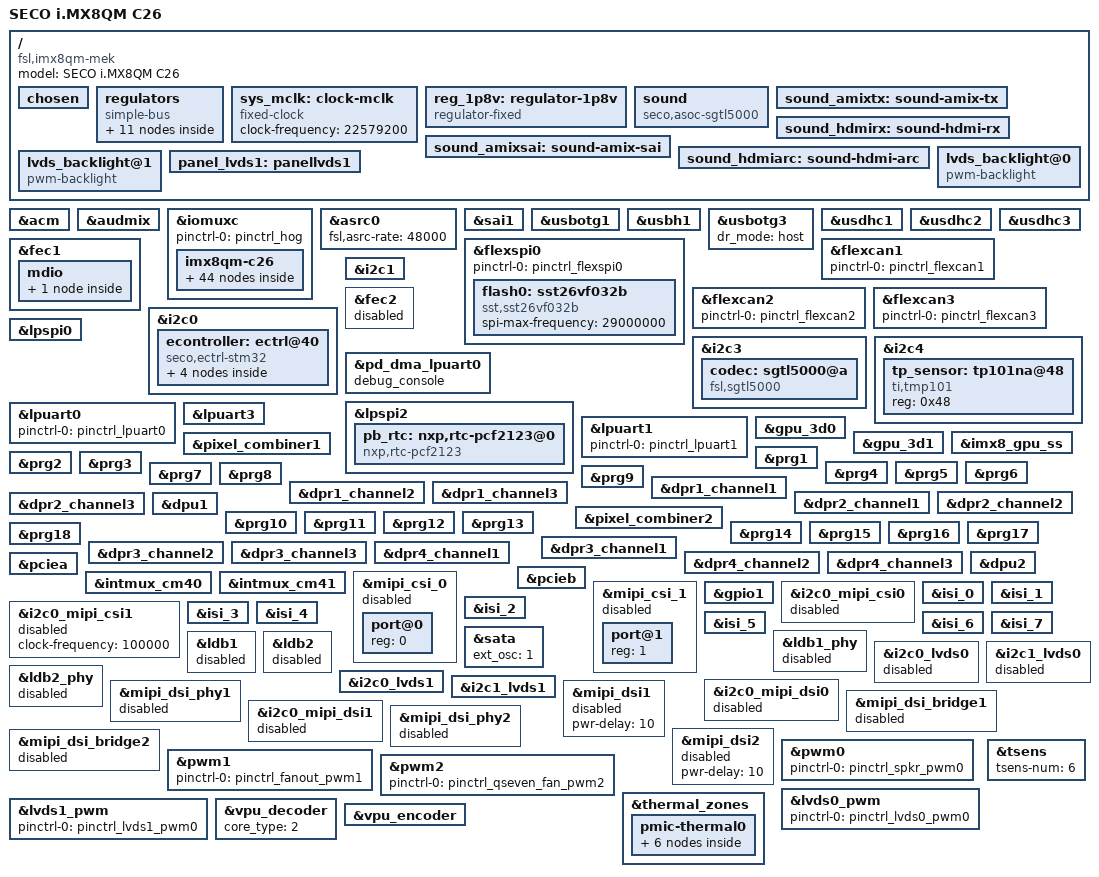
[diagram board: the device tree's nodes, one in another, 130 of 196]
/*
 * Copyright 2017-2018 NXP
 *
 * This program is free software; you can redistribute it and/or
 * modify it under the terms of the GNU General Public License
 * as published by the Free Software Foundation; either version 2
 * of the License, or (at your option) any later version.
 *
 * This program is distributed in the hope that it will be useful,
 * but WITHOUT ANY WARRANTY; without even the implied warranty of
 * MERCHANTABILITY or FITNESS FOR A PARTICULAR PURPOSE.  See the
 * GNU General Public License for more details.
 */

/dts-v1/;

#include <dt-bindings/usb/pd.h>
#include "seco-imx8qm.dtsi"
#include "dt-bindings/net/ti-dp83867.h"
#include "dt-bindings/seco/ectrl_stm32.h"

/ {
	model = "SECO i.MX8QM C26";
	compatible = "fsl,imx8qm-mek","seco,imx8qm-c26","fsl,imx8qm";

	chosen {
		bootargs = "console=ttyLP0,115200 earlycon=lpuart32,0x5a060000,115200";
		stdout-path = &lpuart0;
	};

	regulators {
		compatible = "simple-bus";
		#address-cells = <1>;
		#size-cells = <0>;

		reg_usdhc2_vmmc: usdhc2_vmmc {
			compatible = "regulator-fixed";
			regulator-name = "sw-3p3-sd1";
			regulator-min-microvolt = <3300000>;
			regulator-max-microvolt = <3300000>;
			gpio = <&gpio4 7 GPIO_ACTIVE_HIGH>;
			off-on-delay = <4800>;
			enable-active-high;
		};

		reg_usdhc3_vmmc: usdhc3_vmmc {
			compatible = "regulator-fixed";
			regulator-name = "sw-3p3-sd2";
			regulator-min-microvolt = <3300000>;
			regulator-max-microvolt = <3300000>;
			gpio = <&gpio4 9 GPIO_ACTIVE_HIGH>;
			off-on-delay = <4800>;
			enable-active-high;
		};

		reg_usdhc3_sdiopwr: usdhc3_sdiopwr {
			compatible = "regulator-fixed";
			regulator-name = "sw-3p3-sd2-sdiopwr";
			regulator-min-microvolt = <3300000>;
			regulator-max-microvolt = <3300000>;
			gpio = <&gpio2 4 GPIO_ACTIVE_LOW>;
			regulator-always-on;
			enable-active-low;
			regulator-boot-on;
		};

		reg_vref_1v8: adc_vref_1v8 {
			compatible = "regulator-fixed";
			regulator-name = "vref_1v8";
			regulator-min-microvolt = <1800000>;
			regulator-max-microvolt = <1800000>;
		};

		reg_usb_hsic_rst: usb_hsicrst {
			compatible = "regulator-fixed";
			regulator-name = "HSIC RST";
			regulator-min-microvolt = <3300000>;
			regulator-max-microvolt = <3300000>;
			gpio = <&gpio4 6 GPIO_ACTIVE_HIGH>;
			enable-active-high;
			regulator-always-on;
		};

                pcie_clk_oe_1: pcie_clk_oe1 {
                        compatible = "regulator-fixed";
                        regulator-name = "PCIE_CLK_OE_1";
                        regulator-min-microvolt = <3300000>;
                        regulator-max-microvolt = <3300000>;
                        gpio = <&gpio6 12 GPIO_ACTIVE_HIGH>;
                        enable-active-high;
                        regulator-always-on;
                };

                pcie_clk_oe_2: pcie_clk_oe2 {
                        compatible = "regulator-fixed";
                        regulator-name = "PCIE_CLK_OE_2";
                        regulator-min-microvolt = <3300000>;
                        regulator-max-microvolt = <3300000>;
                        gpio = <&gpio6 13 GPIO_ACTIVE_HIGH>;
                        enable-active-high;
                        regulator-always-on;
                };

                usb_hub_reset: usb_hubrst {
                        compatible = "regulator-fixed";
                        regulator-name = "USB_RST";
                        regulator-min-microvolt = <3300000>;
                        regulator-max-microvolt = <3300000>;
                        gpio = <&gpio4 3 GPIO_ACTIVE_HIGH>;
                        enable-active-high;
                        regulator-always-on;
                };

                lvds_ppen: lvdsppen {
                        compatible = "regulator-fixed";
                        regulator-name = "LVDS_PPEN";
                        regulator-min-microvolt = <3300000>;
                        regulator-max-microvolt = <3300000>;
                        gpio = <&gpio1 5 GPIO_ACTIVE_HIGH>;
                        enable-active-high;
                        regulator-always-on;
			regulator-boot-on;
                };

                lvds_blken: lvdsblken {
                        compatible = "regulator-fixed";
                        regulator-name = "LVDS_BLEN";
                        regulator-min-microvolt = <3300000>;
                        regulator-max-microvolt = <3300000>;
                        gpio = <&gpio2 7 GPIO_ACTIVE_HIGH>;
                        enable-active-high;
                        regulator-always-on;
			regulator-boot-on;
                };

                otg1_pwr_en: otg1_pwren {
                        compatible = "regulator-fixed";
                        regulator-name = "OTG1 PWR EN";
                        regulator-min-microvolt = <3300000>;
                        regulator-max-microvolt = <3300000>;
                        gpio = <&gpio2 19 GPIO_ACTIVE_HIGH>;
                        enable-active-high;
                };
	};

        sys_mclk: clock-mclk {
                compatible = "fixed-clock";
                #clock-cells = <0>;
                clock-frequency = <22579200>;
        };

        reg_1p8v: regulator-1p8v {
                compatible = "regulator-fixed";
                regulator-name = "1P8V";
                regulator-min-microvolt = <1800000>;
                regulator-max-microvolt = <1800000>;
                regulator-always-on;
        };

	sound {
		 compatible = "seco,asoc-sgtl5000";
                model = "seco_sgtl5000";
                cpu-dai = <&sai1>;
                audio-codec = <&codec>;
                /*asrc-controller = <&asrc0>;*/
                status = "okay";

	};

	sound_amixtx: sound-amix-tx {

        };

	sound_hdmirx: sound-hdmi-rx {

	};
	
	sound_amixsai: sound-amix-sai {
	};

	sound_hdmiarc: sound-hdmi-arc {

	};

	lvds_backlight@0 {
		compatible = "pwm-backlight";
		pwms = <&lvds0_pwm 0 100000 0>;

		brightness-levels = < 0  1  2  3  4  5  6  7  8  9
				     10 11 12 13 14 15 16 17 18 19
				     20 21 22 23 24 25 26 27 28 29
				     30 31 32 33 34 35 36 37 38 39
				     40 41 42 43 44 45 46 47 48 49
				     50 51 52 53 54 55 56 57 58 59
				     60 61 62 63 64 65 66 67 68 69
				     70 71 72 73 74 75 76 77 78 79
				     80 81 82 83 84 85 86 87 88 89
				     90 91 92 93 94 95 96 97 98 99
				    100>;
		default-brightness-level = <80>;
	};

	lvds_backlight@1 {
		compatible = "pwm-backlight";
		pwms = <&lvds1_pwm 0 100000 0>;

		brightness-levels = < 0  1  2  3  4  5  6  7  8  9
				     10 11 12 13 14 15 16 17 18 19
				     20 21 22 23 24 25 26 27 28 29
				     30 31 32 33 34 35 36 37 38 39
				     40 41 42 43 44 45 46 47 48 49
				     50 51 52 53 54 55 56 57 58 59
				     60 61 62 63 64 65 66 67 68 69
				     70 71 72 73 74 75 76 77 78 79
				     80 81 82 83 84 85 86 87 88 89
				     90 91 92 93 94 95 96 97 98 99
				    100>;
		default-brightness-level = <80>;
	};
};

&acm {
	status = "okay";
};

&audmix {
	status = "okay";
};

&iomuxc {
	pinctrl-names = "default";
	pinctrl-0 = <&pinctrl_hog>;

	imx8qm-c26 {
		pinctrl_hog: hoggrp {
			fsl,pins = <
				SC_P_MCLK_OUT0_AUD_ACM_MCLK_OUT0	0x0600004c
				SC_P_QSPI1A_DATA1_LSIO_GPIO4_IO25	0x0600004c
				SC_P_SCU_GPIO0_03_LSIO_GPIO0_IO31	0x0600004c
				SC_P_USB_SS3_TC3_LSIO_GPIO4_IO06	0x00000021
				/* SDIO_PWR */
				SC_P_ESAI1_FSR_LSIO_GPIO2_IO04		0x00000021
				/* PCIE CLK OE 1 */
				SC_P_ENET1_RGMII_TXD0_LSIO_GPIO6_IO12	0x00000021
				/* PCIE CLK OE 0 */
				SC_P_ENET1_RGMII_TXD1_LSIO_GPIO6_IO13	0x00000021
				/* USB HUB RESET */
				SC_P_USB_SS3_TC0_LSIO_GPIO4_IO03	0x00000021	
				/* LVDS0 */
				SC_P_LVDS0_GPIO01_LSIO_GPIO1_IO05	0x00000021 /* LVDS_PPEN */	
				SC_P_ESAI1_SCKT_LSIO_GPIO2_IO07		0x00000021 /* LVDS_BLEN */
				/* OTG1 PWR EN */
				SC_P_SPI3_SDI_LSIO_GPIO2_IO19		0x00000021
				/* Generic Gpios */
				SC_P_QSPI1A_SCLK_LSIO_GPIO4_IO21	0x00000021 /* Q7_GPIO0 */
				SC_P_QSPI1A_SS0_B_LSIO_GPIO4_IO19	0x00000021 /* Q7_GPIO1 */	
				SC_P_QSPI1A_SS1_B_LSIO_GPIO4_IO20	0x00000021 /* Q7_GPIO2 */
				SC_P_QSPI1A_DQS_LSIO_GPIO4_IO22		0x00000021 /* Q7_GPIO3 */
				SC_P_QSPI1A_DATA0_LSIO_GPIO4_IO26	0x00000021 /* Q7_GPIO4 */	
				SC_P_QSPI1A_DATA1_LSIO_GPIO4_IO25	0x00000021 /* Q7_GPIO5 */	
				SC_P_QSPI1A_DATA2_LSIO_GPIO4_IO24	0x00000021 /* Q7_GPIO6 */	
				SC_P_QSPI1A_DATA3_LSIO_GPIO4_IO23	0x00000021 /* Q7_GPIO7 */	
				SC_P_SPI3_SCK_LSIO_GPIO2_IO17		0x00000021 /* Q7_GPIO_OUT0 */ 
				/* Gpio switches */
				SC_P_SCU_GPIO0_05_LSIO_GPIO1_IO01	0x00000021 /* BOARD_HOT */
				SC_P_ESAI0_SCKT_LSIO_GPIO2_IO25		0x00000021 /* HDMI_IN_MUX_SEL1 */
				SC_P_ESAI0_TX0_LSIO_GPIO2_IO26		0x00000021 /* HDMI_IN_MUX_SEL2 */
				SC_P_ESAI0_TX1_LSIO_GPIO2_IO27		0x00000021 /* HDMI_IN_MUX_EN */
				SC_P_ESAI0_TX2_RX3_LSIO_GPIO2_IO28	0x00000021 /* USDHC1_VCC_EN */
				SC_P_ESAI0_TX3_RX2_LSIO_GPIO2_IO29	0x00000021 /* USDHC2_VCC_EN */
				/* SECO_CODE */
				SC_P_SIM0_CLK_LSIO_GPIO0_IO00		0x00000021 /* SECO_CODE_0 */	
				SC_P_SIM0_IO_LSIO_GPIO0_IO02		0x00000021 /* SECO_CODE_1 */ 	
				SC_P_SIM0_RST_LSIO_GPIO0_IO01		0x00000021 /* SECO_CODE_2 */	
				SC_P_SIM0_GPIO0_00_LSIO_GPIO0_IO05	0x00000021 /* SECO_CODE_3 */	
				
				SC_P_ESAI0_SCKT_LSIO_GPIO2_IO25		0x00000021 /* HDMI_IN_MUX_SEL1 */
				SC_P_ESAI0_TX0_LSIO_GPIO2_IO26		0x00000021 /* HDMI_IN_MUX_SEL2 */	
				SC_P_ESAI0_TX1_LSIO_GPIO2_IO27		0x00000021 /* HDMI_IN_MUX_EN */	
				/* STM32 Pins */
				SC_P_ESAI0_TX4_RX1_LSIO_GPIO2_IO30	0x00000021 /* From ectrl to SoC */
				SC_P_ESAI0_TX5_RX0_LSIO_GPIO2_IO31	0x00000021 /* From SoC to ectrl */
				SC_P_GPT1_CLK_LSIO_GPIO0_IO17		0x00000021 /* SMB_ALERT# */	
				/* USB Over Current signals */
				SC_P_ESAI1_TX5_RX0_LSIO_GPIO2_IO13	0x00000021 /* USB_01_OC# - GPIO 45 */
				SC_P_ESAI1_TX4_RX1_LSIO_GPIO2_IO12	0x00000021 /* USB_23_OC# - GPIO 44 */
				SC_P_ESAI1_TX3_RX2_LSIO_GPIO2_IO11	0x00000021 /* USB_45_OC# - GPIO 43 */	
				SC_P_ESAI1_TX2_RX3_LSIO_GPIO2_IO10	0x00000021 /* USB_67_OC# - GPIO 42 */	
				/* Audio */
				SC_P_SPDIF0_TX_LSIO_GPIO2_IO15		0x00000021 /* AUD_RST# */	
				/* HDMI IN - Mux Sel */
				SC_P_ESAI0_SCKT_LSIO_GPIO2_IO25		0x00000021 /* HDMI IN - HDMI_IN_MUX_SEL1 */
				SC_P_ESAI0_TX0_LSIO_GPIO2_IO26		0x00000021 /* HDMI IN - HDMI_IN_MUX_SEL2 */
				SC_P_ESAI0_TX1_LSIO_GPIO2_IO27		0x00000021 /* HDMI IN - HDMI_IN_MUX_EN */	
				SC_P_ENET1_RGMII_RXD0_LSIO_GPIO6_IO18	0x00000021 /* HDMI IN - HDMI_RX_EN */
				/* Input Signals */
				SC_P_ESAI0_FSR_LSIO_GPIO2_IO22		0x00000021 /* otg - USB_VBUS_3V3 */	
				SC_P_ESAI1_FST_LSIO_GPIO2_IO05		0x00000021 /* THRMTRIP# */
				SC_P_ESAI1_SCKR_LSIO_GPIO2_IO06		0x00000021 /* THRM# */	
				SC_P_SPI3_SCK_LSIO_GPIO2_IO17		0x00000021 /* QSEVEN_GPIO_OUT0 */
				SC_P_SPI3_SDO_LSIO_GPIO2_IO18		0x00000021 /* SATA_LED */	
				SC_P_SPDIF0_RX_LSIO_GPIO2_IO14		0x00000021 /* RTC_INT */	
				SC_P_SPI3_CS0_LSIO_GPIO2_IO20		0x00000021 /* PMIC1_FSOB */
				SC_P_SPI3_CS1_LSIO_GPIO2_IO21		0x00000021 /* PMIC2_FSOB */	
				SC_P_ENET0_REFCLK_125M_25M_LSIO_GPIO4_IO15	0x00000021 /* LAN_WAKE# */
				SC_P_ENET1_RGMII_TXC_LSIO_GPIO6_IO10	0x00000021 /* CAM0_GPIO1 */	
				SC_P_ENET1_RGMII_TX_CTL_LSIO_GPIO6_IO11	0x00000021 /* CAM1_GPIO1 */	
				SC_P_GPT1_CAPTURE_LSIO_GPIO0_IO18	0x00000021 /* TIMER_IN */
				SC_P_ADC_IN2_LSIO_GPIO3_IO20		0x00000021 /* FAN_TACHO_INT */	
				SC_P_ADC_IN0_LSIO_GPIO3_IO18		0x00000021 /* PMIC1_AMUX */
				SC_P_ADC_IN1_LSIO_GPIO3_IO19		0x00000021 /* PMIC2_AMUX */	
				
			>;
		};

		pinctrl_fec1: fec1grp {
			fsl,pins = <
				SC_P_COMP_CTL_GPIO_1V8_3V3_ENET_ENETB_PAD	0x000014a0
				SC_P_ENET0_MDC_CONN_ENET0_MDC			0x06000020
				SC_P_ENET0_MDIO_CONN_ENET0_MDIO			0x06000020
				SC_P_ENET0_RGMII_TX_CTL_CONN_ENET0_RGMII_TX_CTL	0x00000061
				SC_P_ENET0_RGMII_TXC_CONN_ENET0_RGMII_TXC	0x00000061
				SC_P_ENET0_RGMII_TXD0_CONN_ENET0_RGMII_TXD0	0x00000061
				SC_P_ENET0_RGMII_TXD1_CONN_ENET0_RGMII_TXD1	0x00000061
				SC_P_ENET0_RGMII_TXD2_CONN_ENET0_RGMII_TXD2	0x00000061
				SC_P_ENET0_RGMII_TXD3_CONN_ENET0_RGMII_TXD3	0x00000061
				SC_P_ENET0_RGMII_RXC_CONN_ENET0_RGMII_RXC	0x00000061
				SC_P_ENET0_RGMII_RX_CTL_CONN_ENET0_RGMII_RX_CTL	0x00000061
				SC_P_ENET0_RGMII_RXD0_CONN_ENET0_RGMII_RXD0	0x00000061
				SC_P_ENET0_RGMII_RXD1_CONN_ENET0_RGMII_RXD1	0x00000061
				SC_P_ENET0_RGMII_RXD2_CONN_ENET0_RGMII_RXD2	0x00000061
				SC_P_ENET0_RGMII_RXD3_CONN_ENET0_RGMII_RXD3	0x00000061
				SC_P_ENET1_REFCLK_125M_25M_LSIO_GPIO4_IO16	0x00000021
			>;
		};

		pinctrl_flexcan1: flexcan0grp {
			fsl,pins = <
				SC_P_FLEXCAN0_TX_DMA_FLEXCAN0_TX        0x21
				SC_P_FLEXCAN0_RX_DMA_FLEXCAN0_RX        0x21
			>;
		};

		pinctrl_flexcan2: flexcan1grp {
			fsl,pins = <
				SC_P_FLEXCAN1_TX_DMA_FLEXCAN1_TX        0x21
				SC_P_FLEXCAN1_RX_DMA_FLEXCAN1_RX        0x21
			>;
		};

		pinctrl_flexcan3: flexcan2grp {
			fsl,pins = <
				SC_P_FLEXCAN2_TX_DMA_FLEXCAN2_TX        0x21
				SC_P_FLEXCAN2_RX_DMA_FLEXCAN2_RX        0x21
			>;
		};

		pinctrl_lpuart0: lpuart0grp {
			fsl,pins = <
				SC_P_UART0_RX_DMA_UART0_RX		0x06000020
				SC_P_UART0_TX_DMA_UART0_TX		0x06000020
			>;
		};

		pinctrl_lpuart1: lpuart1grp {
			fsl,pins = <
				SC_P_UART1_RX_DMA_UART1_RX		0x06000020
				SC_P_UART1_TX_DMA_UART1_TX		0x06000020
				SC_P_UART1_CTS_B_DMA_UART1_CTS_B	0x06000020
				SC_P_UART1_RTS_B_DMA_UART1_RTS_B	0x06000020
			>;
		};

		pinctrl_lpuart3: lpuart3grp {
			fsl,pins = <
				SC_P_ENET1_RGMII_RXD3_DMA_UART3_RX	0x06000020
				SC_P_ENET1_RGMII_TXD2_DMA_UART3_TX 	0x06000020
				SC_P_ENET1_RGMII_TXD3_DMA_UART3_RTS_B	0x06000020
				SC_P_ENET1_RGMII_RXC_DMA_UART3_CTS_B	0x06000020	
				
			>;
		};


		pinctrl_sai1: sai1grp {
			fsl,pins = <
				SC_P_SAI1_RXD_AUD_SAI1_RXD		0x06000040
				SC_P_SAI1_TXD_AUD_SAI1_TXD		0x06000060
				SC_P_SAI1_TXFS_AUD_SAI1_TXFS		0x06000060
				SC_P_SAI1_TXC_AUD_SAI1_TXC		0x06000040
			>;
		};

		pinctrl_i2c0: i2c0grp {
			fsl,pins = <
				SC_P_HDMI_TX0_TS_SCL_DMA_I2C0_SCL	0x06000021
				SC_P_HDMI_TX0_TS_SDA_DMA_I2C0_SDA	0x06000021
			>;
		};

		pinctrl_i2c1: i2c1grp {
			fsl,pins = <
				SC_P_GPT0_CLK_DMA_I2C1_SCL 0x0600004c
				SC_P_GPT0_CAPTURE_DMA_I2C1_SDA 0x0600004c
			>;
		};

		pinctrl_i2c3: i2c3grp {
			fsl,pins = <
				SC_P_SIM0_PD_DMA_I2C3_SCL	0x0600004c
				SC_P_SIM0_POWER_EN_DMA_I2C3_SDA 0x0600004c
			>;
		};

		pinctrl_i2c4: i2c4grp {
			fsl,pins = <
				SC_P_ENET1_MDC_DMA_I2C4_SCL 	0x0600004c
				SC_P_ENET1_MDIO_DMA_I2C4_SDA	0x0600004c
			>;
		};

		pinctrl_pciea: pcieagrp{
			fsl,pins = <
				SC_P_PCIE_CTRL0_WAKE_B_LSIO_GPIO4_IO28		0x04000021
				SC_P_PCIE_CTRL0_PERST_B_LSIO_GPIO4_IO29		0x06000021
			>;
		};

		pinctrl_pcieb: pciebgrp{
			fsl,pins = <
				SC_P_PCIE_CTRL1_WAKE_B_LSIO_GPIO4_IO31		0x04000021
				SC_P_PCIE_CTRL1_PERST_B_LSIO_GPIO5_IO00		0x06000021
			>;
		};

		pinctrl_usdhc1: usdhc1grp {
			fsl,pins = <
				SC_P_EMMC0_CLK_CONN_EMMC0_CLK		0x06000041
				SC_P_EMMC0_CMD_CONN_EMMC0_CMD		0x00000021
				SC_P_EMMC0_DATA0_CONN_EMMC0_DATA0	0x00000021
				SC_P_EMMC0_DATA1_CONN_EMMC0_DATA1	0x00000021
				SC_P_EMMC0_DATA2_CONN_EMMC0_DATA2	0x00000021
				SC_P_EMMC0_DATA3_CONN_EMMC0_DATA3	0x00000021
				SC_P_EMMC0_DATA4_CONN_EMMC0_DATA4	0x00000021
				SC_P_EMMC0_DATA5_CONN_EMMC0_DATA5	0x00000021
				SC_P_EMMC0_DATA6_CONN_EMMC0_DATA6	0x00000021
				SC_P_EMMC0_DATA7_CONN_EMMC0_DATA7	0x00000021
				SC_P_EMMC0_STROBE_CONN_EMMC0_STROBE	0x00000041
				SC_P_EMMC0_RESET_B_CONN_EMMC0_RESET_B	0x00000021
			>;
		};

		pinctrl_usdhc1_100mhz: usdhc1grp100mhz {
			fsl,pins = <
				SC_P_EMMC0_CLK_CONN_EMMC0_CLK		0x06000040
				SC_P_EMMC0_CMD_CONN_EMMC0_CMD		0x00000020
				SC_P_EMMC0_DATA0_CONN_EMMC0_DATA0	0x00000020
				SC_P_EMMC0_DATA1_CONN_EMMC0_DATA1	0x00000020
				SC_P_EMMC0_DATA2_CONN_EMMC0_DATA2	0x00000020
				SC_P_EMMC0_DATA3_CONN_EMMC0_DATA3	0x00000020
				SC_P_EMMC0_DATA4_CONN_EMMC0_DATA4	0x00000020
				SC_P_EMMC0_DATA5_CONN_EMMC0_DATA5	0x00000020
				SC_P_EMMC0_DATA6_CONN_EMMC0_DATA6	0x00000020
				SC_P_EMMC0_DATA7_CONN_EMMC0_DATA7	0x00000020
				SC_P_EMMC0_STROBE_CONN_EMMC0_STROBE	0x00000040
				SC_P_EMMC0_RESET_B_CONN_EMMC0_RESET_B	0x00000020
			>;
		};

		pinctrl_usdhc1_200mhz: usdhc1grp200mhz {
			fsl,pins = <
				SC_P_EMMC0_CLK_CONN_EMMC0_CLK		0x06000040
				SC_P_EMMC0_CMD_CONN_EMMC0_CMD		0x00000020
				SC_P_EMMC0_DATA0_CONN_EMMC0_DATA0	0x00000020
				SC_P_EMMC0_DATA1_CONN_EMMC0_DATA1	0x00000020
				SC_P_EMMC0_DATA2_CONN_EMMC0_DATA2	0x00000020
				SC_P_EMMC0_DATA3_CONN_EMMC0_DATA3	0x00000020
				SC_P_EMMC0_DATA4_CONN_EMMC0_DATA4	0x00000020
				SC_P_EMMC0_DATA5_CONN_EMMC0_DATA5	0x00000020
				SC_P_EMMC0_DATA6_CONN_EMMC0_DATA6	0x00000020
				SC_P_EMMC0_DATA7_CONN_EMMC0_DATA7	0x00000020
				SC_P_EMMC0_STROBE_CONN_EMMC0_STROBE	0x00000040
				SC_P_EMMC0_RESET_B_CONN_EMMC0_RESET_B	0x00000020
			>;
		};

		pinctrl_usdhc2_gpio: usdhc2grpgpio {
			fsl,pins = <
				SC_P_USDHC1_DATA7_LSIO_GPIO5_IO22	0x00000021
				SC_P_USDHC1_RESET_B_LSIO_GPIO4_IO07	0x00000021
			>;
		};

		pinctrl_usdhc2: usdhc2grp {
			fsl,pins = <
				SC_P_USDHC1_CLK_CONN_USDHC1_CLK		0x06000041
				SC_P_USDHC1_CMD_CONN_USDHC1_CMD		0x00000021
				SC_P_USDHC1_DATA0_CONN_USDHC1_DATA0	0x00000021
				SC_P_USDHC1_DATA1_CONN_USDHC1_DATA1	0x00000021
				SC_P_USDHC1_DATA2_CONN_USDHC1_DATA2	0x00000021
				SC_P_USDHC1_DATA3_CONN_USDHC1_DATA3	0x00000021
				SC_P_USDHC1_VSELECT_CONN_USDHC1_VSELECT	0x00000021
			>;
		};

		pinctrl_usdhc2_100mhz: usdhc2grp100mhz {
			fsl,pins = <
				SC_P_USDHC1_CLK_CONN_USDHC1_CLK		0x06000040
				SC_P_USDHC1_CMD_CONN_USDHC1_CMD		0x00000020
				SC_P_USDHC1_DATA0_CONN_USDHC1_DATA0	0x00000020
				SC_P_USDHC1_DATA1_CONN_USDHC1_DATA1	0x00000020
				SC_P_USDHC1_DATA2_CONN_USDHC1_DATA2	0x00000020
				SC_P_USDHC1_DATA3_CONN_USDHC1_DATA3	0x00000020
				SC_P_USDHC1_VSELECT_CONN_USDHC1_VSELECT	0x00000020
			>;
		};

		pinctrl_usdhc2_200mhz: usdhc2grp200mhz {
			fsl,pins = <
				SC_P_USDHC1_CLK_CONN_USDHC1_CLK		0x06000040
				SC_P_USDHC1_CMD_CONN_USDHC1_CMD		0x00000020
				SC_P_USDHC1_DATA0_CONN_USDHC1_DATA0	0x00000020
				SC_P_USDHC1_DATA1_CONN_USDHC1_DATA1	0x00000020
				SC_P_USDHC1_DATA2_CONN_USDHC1_DATA2	0x00000020
				SC_P_USDHC1_DATA3_CONN_USDHC1_DATA3	0x00000020
				SC_P_USDHC1_VSELECT_CONN_USDHC1_VSELECT	0x00000020
			>;
		};

		pinctrl_usdhc3_gpio: usdhc3grpgpio {
			fsl,pins = <
				SC_P_USDHC2_CD_B_LSIO_GPIO4_IO12 	0x00000021 /* Card Detect */
				SC_P_USDHC2_WP_LSIO_GPIO4_IO11		0x00000021 /* Write Protect */
				SC_P_USDHC2_RESET_B_LSIO_GPIO4_IO09	0x00000021
			>;
		};

		pinctrl_usdhc3: usdhc3grp {
			fsl,pins = <
				SC_P_USDHC2_CLK_CONN_USDHC2_CLK		0x06000040
				SC_P_USDHC2_CMD_CONN_USDHC2_CMD		0x00000020
				SC_P_USDHC2_DATA0_CONN_USDHC2_DATA0	0x00000020
				SC_P_USDHC2_DATA1_CONN_USDHC2_DATA1	0x00000020
				SC_P_USDHC2_DATA2_CONN_USDHC2_DATA2	0x00000020
				SC_P_USDHC2_DATA3_CONN_USDHC2_DATA3	0x00000020
				SC_P_USDHC2_VSELECT_CONN_USDHC2_VSELECT	0x00000020
			>;
		};

		pinctrl_lvds0_lpi2c0: lvds0lpi2c0grp {
			fsl,pins = <
				SC_P_LVDS0_I2C0_SCL_LVDS0_I2C0_SCL	0xc600004c
				SC_P_LVDS0_I2C0_SDA_LVDS0_I2C0_SDA	0xc600004c
			>;
		};

		pinctrl_lvds0_lpi2c1: lvds0lpi2c1grp {
			fsl,pins = <
				SC_P_LVDS0_I2C1_SCL_LVDS0_I2C1_SCL	0xc600004c
				SC_P_LVDS0_I2C1_SDA_LVDS0_I2C1_SDA	0xc600004c
			>;
		};

		pinctrl_lvds1_lpi2c0: lvds1lpi2c0grp {
			fsl,pins = <
				SC_P_LVDS1_I2C0_SCL_LVDS1_I2C0_SCL	0xc600004c
				SC_P_LVDS1_I2C0_SDA_LVDS1_I2C0_SDA	0xc600004c
			>;
		};

		pinctrl_lvds1_lpi2c1: lvds1lpi2c1grp {
			fsl,pins = <
				SC_P_LVDS1_I2C1_SCL_LVDS1_I2C1_SCL	0xc600004c
				SC_P_LVDS1_I2C1_SDA_LVDS1_I2C1_SDA	0xc600004c
			>;
		};

		pinctrl_lvds0_pwm0: lvds0pwm0grp {
			fsl,pins = <
				SC_P_LVDS0_GPIO00_LVDS0_PWM0_OUT	0x00000020
			>;
		};

		pinctrl_lvds1_pwm0: lvds1pwm0grp {
			fsl,pins = <
				SC_P_LVDS1_GPIO00_LVDS1_PWM0_OUT	0x00000020
			>;
		};

		pinctrl_spkr_pwm0: qseven_spkr_pwm0grp {
			fsl,pins = <
				SC_P_UART0_RTS_B_LSIO_PWM0_OUT		0x00000020
			>;
		};

		pinctrl_fanout_pwm1: qseven_fanout_pwm1grp {
                        fsl,pins = <
				SC_P_UART0_CTS_B_LSIO_PWM1_OUT		0x00000020
                        >;
                };

		pinctrl_qseven_fan_pwm2: qseven_fan_pwm2grp {
			fsl,pins = <
				SC_P_GPT1_COMPARE_LSIO_PWM2_OUT		0x00000020
			>;
		};

		pinctrl_mipi0_lpi2c0: mipi0_lpi2c0grp {
			fsl,pins = <
				SC_P_MIPI_DSI0_I2C0_SCL_MIPI_DSI0_I2C0_SCL	0xc600004c
				SC_P_MIPI_DSI0_I2C0_SDA_MIPI_DSI0_I2C0_SDA	0xc600004c
				SC_P_MIPI_DSI0_GPIO0_01_LSIO_GPIO1_IO19		0x00000020
			>;
		};

		pinctrl_mipi1_lpi2c0: mipi1_lpi2c0grp {
			fsl,pins = <
				SC_P_MIPI_DSI1_I2C0_SCL_MIPI_DSI1_I2C0_SCL	0xc600004c
				SC_P_MIPI_DSI1_I2C0_SDA_MIPI_DSI1_I2C0_SDA	0xc600004c
				SC_P_MIPI_DSI1_GPIO0_01_LSIO_GPIO1_IO23		0x00000020
			>;
		};

		pinctrl_mipi_csi0_i2c: mipicsi0i2cgrp{
                        fsl,pins = <
                		SC_P_MIPI_CSI0_I2C0_SCL_MIPI_CSI0_I2C0_SCL      0x2000060
		                SC_P_MIPI_CSI0_I2C0_SDA_MIPI_CSI0_I2C0_SDA      0x2000060
                        >;
                };

		pinctrl_mipi_csi0_camera: mipicsi0grp{
                        fsl,pins = <
                                SC_P_MIPI_CSI0_MCLK_OUT_MIPI_CSI0_ACM_MCLK_OUT  0xC0000041
                                SC_P_MIPI_CSI0_GPIO0_00_LSIO_GPIO1_IO27 	0x00000021  // MIPI_CSI0_RST_B  - GPIO 475
                                SC_P_MIPI_CSI0_GPIO0_01_LSIO_GPIO1_IO28 	0x00000021  // MIPI_CSI0_EN     - GPIO 476
                        >;
                };

		pinctrl_mipi_csi1_camera: mipicsi1grp{
                        fsl,pins = <
                                SC_P_MIPI_CSI1_MCLK_OUT_MIPI_CSI1_ACM_MCLK_OUT  0xC0000041
                                SC_P_MIPI_CSI1_GPIO0_00_LSIO_GPIO1_IO30 	0x00000021  // MIPI_CSI0_RST_B  - GPIO 475
                                SC_P_MIPI_CSI1_GPIO0_01_LSIO_GPIO1_IO31 	0x00000021  // MIPI_CSI0_EN     - GPIO 476
                        >;
                };

		pinctrl_mipi_csi1_en_rst: mipi_csi1_en_rst {
			fsl,pins = <
				SC_P_MIPI_CSI1_GPIO0_00_LSIO_GPIO1_IO30         0x00000021
				SC_P_MIPI_CSI1_GPIO0_01_LSIO_GPIO1_IO31         0x00000021
			>;
                };

		pinctrl_usb_hsic_idle: usbh1_1 {
                        fsl,pins = <
                                SC_P_USB_HSIC0_DATA_CONN_USB_HSIC0_DATA         0xc60000c7
                                SC_P_USB_HSIC0_STROBE_CONN_USB_HSIC0_STROBE     0xc60000c7
                        >;
		};

		pinctrl_usb_hsic_active: usbh1_2 {
			    fsl,pins = <
				SC_P_USB_HSIC0_STROBE_CONN_USB_HSIC0_STROBE     0xc60000d7
		    >;
		};

		pinctrl_lpspi0: lpspi1grp {
                        fsl,pins = <
				SC_P_SPI0_SCK_DMA_SPI0_SCK              0x0600004c
				SC_P_SPI0_SDO_DMA_SPI0_SDO              0x0600004c
				SC_P_SPI0_SDI_DMA_SPI0_SDI              0x0600004c
				SC_P_SPI0_CS0_LSIO_GPIO3_IO05		0x00000021  
				SC_P_SPI0_CS1_LSIO_GPIO3_IO06		0x00000021  
                        >;
                };

		pinctrl_lpspi2: lpspi2grp {
                        fsl,pins = <
				SC_P_SPI2_SCK_DMA_SPI2_SCK              0x0600004c
				SC_P_SPI2_SDO_DMA_SPI2_SDO              0x0600004c
				SC_P_SPI2_SDI_DMA_SPI2_SDI              0x0600004c
				SC_P_SPI2_CS0_LSIO_GPIO3_IO10		0x00000021  // DM_SPI2_CS0 - GPIO 394
                        >;
                };

		pinctrl_flexspi0: flexspi0grp {
                        fsl,pins = <
                                SC_P_QSPI0A_DATA0_LSIO_QSPI0A_DATA0     0x0600004c
                                SC_P_QSPI0A_DATA1_LSIO_QSPI0A_DATA1     0x0600004c
                                SC_P_QSPI0A_DATA2_LSIO_QSPI0A_DATA2     0x0600004c
                                SC_P_QSPI0A_DATA3_LSIO_QSPI0A_DATA3     0x0600004c
                                SC_P_QSPI0A_SS0_B_LSIO_QSPI0A_SS0_B     0x0600004c
                        >;
                };



	};
};

&asrc0 {
	fsl,asrc-rate  = <48000>;
	status = "okay";
};

&sai1 {
	assigned-clocks = <&clk IMX8QM_ACM_SAI1_MCLK_SEL>,
			<&clk IMX8QM_AUD_PLL1_DIV>,
			<&clk IMX8QM_AUD_ACM_AUD_PLL_CLK1_DIV>,
			<&clk IMX8QM_AUD_ACM_AUD_REC_CLK1_DIV>,
			<&clk IMX8QM_AUD_SAI_1_MCLK>;
	assigned-clock-parents = <&clk IMX8QM_AUD_ACM_AUD_PLL_CLK1_CLK>;
	assigned-clock-rates = <90316800>, <722534400>, <90316800>, <11289600>, <90316800>;

	pinctrl-names = "default";
	pinctrl-0 = <&pinctrl_sai1>;
	status = "okay";
};

&usbotg1 {
	dr_mode = "otg";
	ci-disable-lpm;
	vbus-supply = <&otg1_pwr_en>;
	status = "okay";
};

/*
 * Due to USB HSIC uses the same AHB and 480M with USBOTG1,
 * the usbotg1 must be enabled for usbh1 usage.
 */

&usbh1 {
        pinctrl-names = "idle", "active";
        pinctrl-0 = <&pinctrl_usb_hsic_idle>;
        pinctrl-1 = <&pinctrl_usb_hsic_active>;
        srp-disable;
        hnp-disable;
        adp-disable;
        disable-over-current;
        status = "okay";
};

&usbotg3 {
	dr_mode = "host";
	status = "okay";
};

&usdhc1 {
	pinctrl-names = "default", "state_100mhz", "state_200mhz";
	pinctrl-0 = <&pinctrl_usdhc1>;
	pinctrl-1 = <&pinctrl_usdhc1_100mhz>;
	pinctrl-2 = <&pinctrl_usdhc1_200mhz>;
	bus-width = <8>;
	non-removable;
	status = "okay";
};

&usdhc2 {
	pinctrl-names = "default", "state_100mhz", "state_200mhz";
	pinctrl-0 = <&pinctrl_usdhc2>, <&pinctrl_usdhc2_gpio>;
	pinctrl-1 = <&pinctrl_usdhc2_100mhz>, <&pinctrl_usdhc2_gpio>;
	pinctrl-2 = <&pinctrl_usdhc2_200mhz>, <&pinctrl_usdhc2_gpio>;
	bus-width = <4>;
	cd-gpios = <&gpio5 22 GPIO_ACTIVE_LOW>;
	vmmc-supply = <&reg_usdhc2_vmmc>;
	status = "okay";
};

&usdhc3 {
	pinctrl-names = "default";
	pinctrl-0 = <&pinctrl_usdhc3>, <&pinctrl_usdhc3_gpio>;
	bus-width = <4>;
	no-1-8-v;
	cd-gpios = <&gpio4 12 GPIO_ACTIVE_LOW>;
	wp-gpios = <&gpio4 11 GPIO_ACTIVE_HIGH>;
	vmmc-supply = <&reg_usdhc3_vmmc>;
	status = "okay";
};

&fec1 {
	pinctrl-names = "default";
	pinctrl-0 = <&pinctrl_fec1>;
	phy-mode = "rgmii-id";
	phy-handle = <&ethphy0>;
	fsl,magic-packet;
	phy-reset-gpios = <&gpio4 16 GPIO_ACTIVE_LOW>;
        phy-reset-duration = <2>;
	status = "okay";

	mdio {
		#address-cells = <1>;
		#size-cells = <0>;

		ethphy0: ethernet-phy@9 {
			compatible = "ethernet-phy-ieee802.3-c22";
                        reg = <9>;
                        ti,rx-internal-delay = <DP83867_RGMIIDCTL_2_00_NS>;
                        ti,tx-internal-delay = <DP83867_RGMIIDCTL_2_00_NS>;
                        ti,fifo-depth = <DP83867_PHYCR_FIFO_DEPTH_8_B_NIB>;		
			//ti,leds-conf = <0xbb58>;
			//ti,leds-polarity = <0x444>;

		};

	};
};

&flexspi0 {
        pinctrl-names = "default";
        pinctrl-0 = <&pinctrl_flexspi0>;
        status = "okay";

        flash0: sst26vf032b {
		#address-cells = <1>;
		#size-cells = <1>;
		compatible = "sst,sst26vf032b";//, "jedec,spi-nor";
		spi-max-frequency = <29000000>;
//		spi-nor,ddr-quad-read-dummy = <8>;
        };

};


&flexcan1 {
	pinctrl-names = "default";
	pinctrl-0 = <&pinctrl_flexcan1>;
	status = "okay";
};

&flexcan2 {
	pinctrl-names = "default";
	pinctrl-0 = <&pinctrl_flexcan2>;
	status = "okay";
};

&flexcan3 {
	pinctrl-names = "default";
	pinctrl-0 = <&pinctrl_flexcan3>;
	status = "okay";
};

&i2c0 {
	#address-cells = <1>;
	#size-cells = <0>;
	clock-frequency = <100000>;
	pinctrl-names = "default";
	pinctrl-0 = <&pinctrl_i2c0>;
	status = "okay";

        econtroller: ectrl@40 {
                compatible       = "seco,ectrl-stm32";
                reg              = <0x40>;
		
		board-id	 = "C26";

                interrupt-parent = <&gpio2>;
                interrupts       = <30 0>;

                rb-poff-gpio     = <&gpio2 31 0>;
		
		ectrl,input;

		events           = <ECTRL_EVNT_FAIL_BV 
					ECTRL_EVNT_FAIL_WD  
					ECTRL_EVNT_BATLOW_SIGNAL 
					ECTRL_EVNT_SLEEP_SIGNAL 
					ECTRL_EVNT_LID_SIGNAL 
					ECTRL_EVNT_PWR_BUTTON 
					ECTRL_EVNT_FAIL_PWGIN 
					ECTRL_EVNT_WAKE_EN>;

                boot_device {

                        bootdev@0 {
                                id    = <ECTRL_BOOTDEV_USDHC1>;
                                label = "on board SD";
                        };

                        bootdev@1 {
                                id    = <ECTRL_BOOTDEV_EMMC>;
                                label = "on board eMMC";
                        };

                        bootdev@2 {
                                id    = <ECTRL_BOOTDEV_SPI>;
                                label = "external uSD";
                        };
                };

        };

};

&i2c1 {
	#address-cells = <1>;
	#size-cells = <0>;
	clock-frequency = <100000>;
	pinctrl-names = "default";
	pinctrl-0 = <&pinctrl_i2c1>;
	status = "okay";
	
};

&i2c3 {
	#address-cells = <1>;
	#size-cells = <0>;
	clock-frequency = <100000>;
	pinctrl-names = "default";
	pinctrl-0 = <&pinctrl_i2c3>;
	status = "okay";

        codec: sgtl5000@a {
                #sound-dai-cells = <0>;
                compatible = "fsl,sgtl5000";
                reg = <0xa>;
                VDDA-supply = <&reg_1p8v>;
                VDDIO-supply = <&reg_1p8v>;
		clocks = <&sys_mclk>;
        };

};

&i2c4 {
        #address-cells = <1>;
        #size-cells = <0>;
        clock-frequency = <100000>;
        pinctrl-names = "default";
        pinctrl-0 = <&pinctrl_i2c4>;
        status = "okay";
		
	tp_sensor: tp101na@48 {
		compatible = "ti,tmp101";
		reg = <0x48>;

	};

};

&fec2 {
	status = "disabled";
};

&pd_dma_lpuart0 {
	debug_console;
};

&lpspi0 {
        #address-cells = <1>;
        #size-cells = <0>;
	fsl,spi-num-chipselects = <2>;
        cs-gpios = <&gpio3 5 GPIO_ACTIVE_LOW>,<&gpio3 6 GPIO_ACTIVE_LOW>;
        pinctrl-names = "default";
        pinctrl-0 = <&pinctrl_lpspi0>;
        status = "okay";
};

&lpspi2 {
        #address-cells = <1>;
        #size-cells = <0>;
	fsl,spi-num-chipselects = <1>;
        cs-gpios = <&gpio3 10 GPIO_ACTIVE_LOW>;
        pinctrl-names = "default";
        pinctrl-0 = <&pinctrl_lpspi2>;
        status = "okay";

        pb_rtc: nxp,rtc-pcf2123@0 {
                compatible = "nxp,rtc-pcf2123";
                spi-max-frequency = <1000000>;
                spi-cs-high;
                reg = <0>;
        };

};

&lpuart0 { /* console */
	pinctrl-names = "default";
	pinctrl-0 = <&pinctrl_lpuart0>;
	status = "okay";
};

&lpuart1 { /* CN1 uart */
	pinctrl-names = "default";
	pinctrl-0 = <&pinctrl_lpuart1>;
	status = "okay";
};

&lpuart3 { /* MKbus */
	pinctrl-names = "default";
	pinctrl-0 = <&pinctrl_lpuart3>;
	uart-has-rtscts;
	status = "okay";
};

&gpu_3d0 {
        status = "okay";
};

&gpu_3d1 {
        status = "okay";
};

&imx8_gpu_ss {
        status = "okay";
};

&pixel_combiner1 {
	status = "okay";
};

&prg1 {
	status = "okay";
};

&prg2 {
	status = "okay";
};

&prg3 {
	status = "okay";
};

&prg4 {
	status = "okay";
};

&prg5 {
	status = "okay";
};

&prg6 {
	status = "okay";
};

&prg7 {
	status = "okay";
};

&prg8 {
	status = "okay";
};

&prg9 {
	status = "okay";
};

&dpr1_channel1 {
	status = "okay";
};

&dpr1_channel2 {
	status = "okay";
};

&dpr1_channel3 {
	status = "okay";
};

&dpr2_channel1 {
	status = "okay";
};

&dpr2_channel2 {
	status = "okay";
};

&dpr2_channel3 {
	status = "okay";
};

&dpu1 {
	status = "okay";
};

&pixel_combiner2 {
	status = "okay";
};

&prg10 {
	status = "okay";
};

&prg11 {
	status = "okay";
};

&prg12 {
	status = "okay";
};

&prg13 {
	status = "okay";
};

&prg14 {
	status = "okay";
};

&prg15 {
	status = "okay";
};

&prg16 {
	status = "okay";
};

&prg17 {
	status = "okay";
};

&prg18 {
	status = "okay";
};

&dpr3_channel1 {
	status = "okay";
};

&dpr3_channel2 {
	status = "okay";
};

&dpr3_channel3 {
	status = "okay";
};

&dpr4_channel1 {
	status = "okay";
};

&dpr4_channel2 {
	status = "okay";
};

&dpr4_channel3 {
	status = "okay";
};

&dpu2 {
	status = "okay";
};

&pciea{
	ext_osc = <1>;
	pinctrl-names = "default";
	pinctrl-0 = <&pinctrl_pciea>;
	reset-gpio = <&gpio4 29 GPIO_ACTIVE_LOW>;
	status = "okay";
};

&pcieb{
	ext_osc = <1>;
	pinctrl-names = "default";
	pinctrl-0 = <&pinctrl_pcieb>;
	reset-gpio = <&gpio5 0 GPIO_ACTIVE_LOW>;
	status = "okay";
};

&intmux_cm40 {
	status = "okay";
};

&intmux_cm41 {
	status = "okay";
};

&mipi_csi_0 {
	#address-cells = <1>;
	#size-cells = <0>;
	status = "disabled";

	/* Camera 0  MIPI CSI-2 (CSIS0) */
	port@0 {
		reg = <0>;
	};
};

&mipi_csi_1 {
	#address-cells = <1>;
	#size-cells = <0>;
	status = "disabled";

	/* Camera 0 MIPI CSI-2 (CSIS1) */
	port@1 {
		reg = <1>;
	};
};

&gpio1 {
	status = "okay";
};

&i2c0_mipi_csi0 {
	#address-cells = <1>;
	#size-cells = <0>;
	pinctrl-names = "default";
	pinctrl-0 = <&pinctrl_mipi_csi0_i2c>;
	clock-frequency = <100000>;
	status = "disabled";
};

&i2c0_mipi_csi1 {
	#address-cells = <1>;
	#size-cells = <0>;
	clock-frequency = <100000>;
	status = "disabled";

};

&isi_0 {
	status = "okay";
};

&isi_1 {
	status = "okay";
};

&isi_2 {
	status = "okay";
};

&isi_3 {
	status = "okay";
};

&isi_4 {
       status = "okay";
};

&isi_5 {
       status = "okay";
};

&isi_6 {
       status = "okay";
};

&isi_7 {
       status = "okay";
};



&sata {
	status = "okay";
	ext_osc = <1>;
};

/*
 * LVDS1
 */
/{
	panel_lvds1: panellvds1 {
		#address-cells = <1>;
		#size-cells = <0>;
	};
};
&ldb1_phy {
	status = "disabled";
};

&ldb1 {
	status = "disabled";

};

&i2c0_lvds0 {
	#address-cells = <1>;
	#size-cells = <0>;
	pinctrl-names = "default";
	pinctrl-0 = <&pinctrl_lvds0_lpi2c0>;
	clock-frequency = <100000>;
	status = "disabled";

};

&i2c1_lvds0 {
	#address-cells = <1>;
	#size-cells = <0>;
	pinctrl-names = "default";
	pinctrl-0 = <&pinctrl_lvds0_lpi2c1>;
	clock-frequency = <100000>;
	status = "disabled";

};

/*
 * LVDS2
 */

&ldb2_phy {
	status = "disabled";
};

&ldb2 {
	status = "disabled";

};

&i2c0_lvds1 {
	#address-cells = <1>;
	#size-cells = <0>;
	pinctrl-names = "default";
	pinctrl-0 = <&pinctrl_lvds1_lpi2c0>;
	clock-frequency = <100000>;
	status = "okay";

};

&i2c1_lvds1 {
	#address-cells = <1>;
	#size-cells = <0>;
	pinctrl-names = "default";
	pinctrl-0 = <&pinctrl_lvds1_lpi2c1>;
	clock-frequency = <100000>;
	status = "okay";

};

/*
 * MIPI DSI 
 */

&i2c0_mipi_dsi0 {
	#address-cells = <1>;
	#size-cells = <0>;
	pinctrl-names = "default";
	pinctrl-0 = <&pinctrl_mipi0_lpi2c0>;
	clock-frequency = <100000>;
	status = "disabled";

};

&mipi_dsi_phy1 {
	status = "disabled";
};

&mipi_dsi1 {
	pwr-delay = <10>;
	status = "disabled";
};

&mipi_dsi_bridge1 {
	status = "disabled";
};

&i2c0_mipi_dsi1 {
	#address-cells = <1>;
	#size-cells = <0>;
	pinctrl-names = "default";
	pinctrl-0 = <&pinctrl_mipi1_lpi2c0>;
	clock-frequency = <100000>;
	status = "disabled";

};

&mipi_dsi_phy2 {
	status = "disabled";
};

&mipi_dsi2 {
	pwr-delay = <10>;
	status = "disabled";
};

&mipi_dsi_bridge2 {
	status = "disabled";

};

&pwm0 {
    pinctrl-names = "default";
    pinctrl-0 = <&pinctrl_spkr_pwm0>;
    status = "okay";
};

&pwm1 {
    pinctrl-names = "default";
    pinctrl-0 = <&pinctrl_fanout_pwm1>;
    status = "okay";
};

&pwm2 {
    pinctrl-names = "default";
    pinctrl-0 = <&pinctrl_qseven_fan_pwm2>;
    status = "okay";
};

&lvds0_pwm {
	pinctrl-names = "default";
	pinctrl-0 = <&pinctrl_lvds0_pwm0>;
	status = "okay";
};

&lvds1_pwm {
	pinctrl-names = "default";
	pinctrl-0 = <&pinctrl_lvds1_pwm0>;
	status = "okay";
};

&tsens {
	tsens-num = <6>;
};

&thermal_zones {
	pmic-thermal0 {
		polling-delay-passive = <250>;
		polling-delay = <2000>;
		thermal-sensors = <&tsens 5>;
		trips {
			pmic_alert0: trip0 {
				temperature = <110000>;
				hysteresis = <2000>;
				type = "passive";
			};
			pmic_crit0: trip1 {
				temperature = <125000>;
				hysteresis = <2000>;
				type = "critical";
			};
		};
		cooling-maps {
			map0 {
				trip = <&pmic_alert0>;
				cooling-device =
				<&A53_0 THERMAL_NO_LIMIT THERMAL_NO_LIMIT>;
			};
			map1 {
				trip = <&pmic_alert0>;
				cooling-device =
				<&A72_0 THERMAL_NO_LIMIT THERMAL_NO_LIMIT>;
			};
		};
	};
};

&vpu_decoder {
	core_type = <2>;
	status = "okay";
};

&vpu_encoder {
	status = "okay";
};


